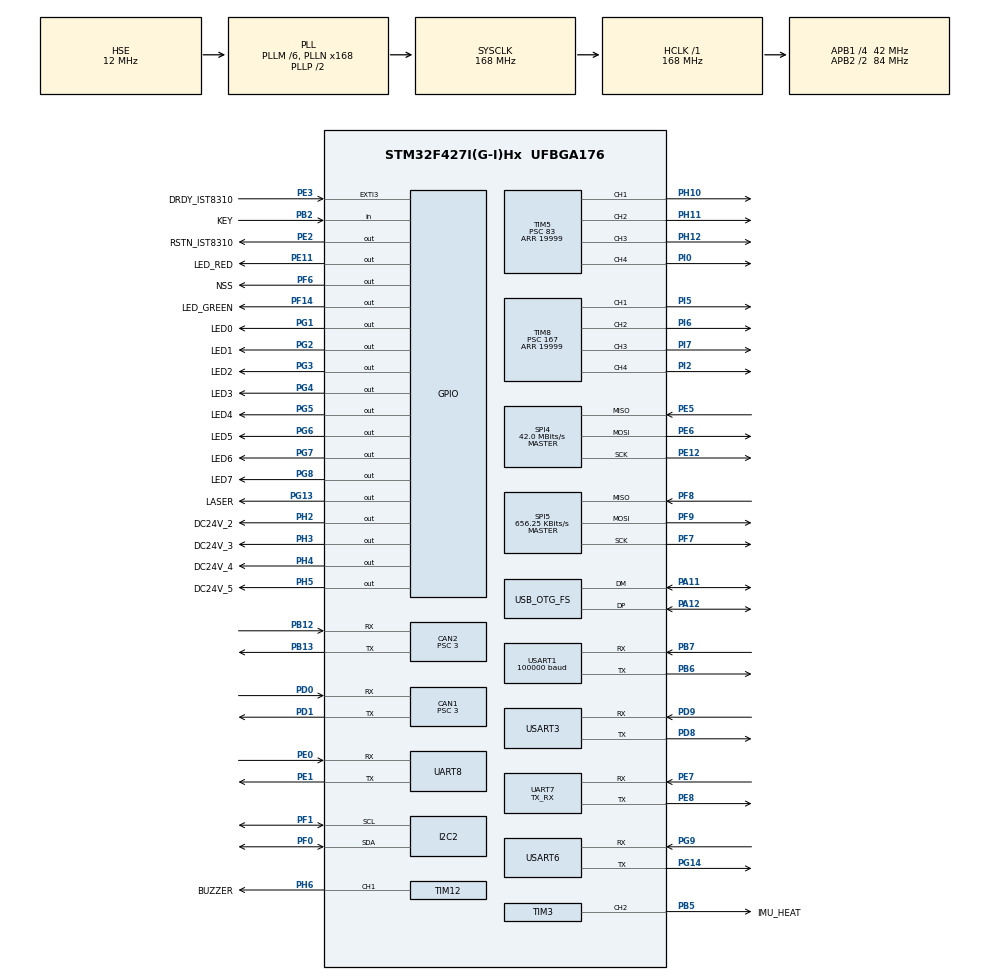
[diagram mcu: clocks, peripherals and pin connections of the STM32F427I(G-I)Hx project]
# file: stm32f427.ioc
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ADC1.Channel-0\#ChannelRegularConversion=ADC_CHANNEL_VREFINT
ADC1.Channel-1\#ChannelRegularConversion=ADC_CHANNEL_VREFINT
ADC1.Channel-2\#ChannelRegularConversion=ADC_CHANNEL_VREFINT
ADC1.Channel-3\#ChannelRegularConversion=ADC_CHANNEL_VREFINT
ADC1.ClockPrescaler=ADC_CLOCK_SYNC_PCLK_DIV4
ADC1.ContinuousConvMode=ENABLE
ADC1.DMAContinuousRequests=DISABLE
ADC1.DataAlign=ADC_DATAALIGN_RIGHT
ADC1.DiscontinuousConvMode=DISABLE
ADC1.EOCSelection=ADC_EOC_SINGLE_CONV
ADC1.EnableAnalogWatchDog=false
ADC1.ExternalTrigConv=ADC_SOFTWARE_START
ADC1.ExternalTrigConvEdge=ADC_EXTERNALTRIGCONVEDGE_NONE
ADC1.InjNumberOfConversion=0
ADC1.NbrOfConversion=4
ADC1.NbrOfConversionFlag=1
ADC1.Rank-0\#ChannelRegularConversion=1
ADC1.Rank-1\#ChannelRegularConversion=2
ADC1.Rank-2\#ChannelRegularConversion=3
ADC1.Rank-3\#ChannelRegularConversion=4
ADC1.Resolution=ADC_RESOLUTION_12B
ADC1.SamplingTime-0\#ChannelRegularConversion=ADC_SAMPLETIME_56CYCLES
ADC1.SamplingTime-1\#ChannelRegularConversion=ADC_SAMPLETIME_56CYCLES
ADC1.SamplingTime-2\#ChannelRegularConversion=ADC_SAMPLETIME_56CYCLES
ADC1.SamplingTime-3\#ChannelRegularConversion=ADC_SAMPLETIME_56CYCLES
ADC1.ScanConvMode=ENABLE
ADC1.master=1
CAN1.ABOM=ENABLE
CAN1.BS1=CAN_BS1_10TQ
CAN1.BS2=CAN_BS2_3TQ
CAN1.CalculateTimeBit=1000
CAN1.CalculateTimeQuantum=71.42857142857143
CAN1.NART=ENABLE
CAN1.Prescaler=3
CAN2.ABOM=ENABLE
CAN2.BS1=CAN_BS1_10TQ
CAN2.BS2=CAN_BS2_3TQ
CAN2.CalculateTimeBit=1000
CAN2.CalculateTimeQuantum=71.42857142857143
CAN2.NART=ENABLE
CAN2.Prescaler=3
Dma.Request0=USART1_RX
Dma.USART1_RX.0.Direction=DMA_PERIPH_TO_MEMORY
Dma.USART1_RX.0.FIFOMode=DMA_FIFOMODE_DISABLE
Dma.USART1_RX.0.Instance=DMA2_Stream2
Dma.USART1_RX.0.MemDataAlignment=DMA_MDATAALIGN_BYTE
Dma.USART1_RX.0.MemInc=DMA_MINC_ENABLE
Dma.USART1_RX.0.Mode=DMA_NORMAL
Dma.USART1_RX.0.PeriphDataAlignment=DMA_PDATAALIGN_BYTE
Dma.USART1_RX.0.PeriphInc=DMA_PINC_DISABLE
Dma.USART1_RX.0.Priority=DMA_PRIORITY_LOW
FREERTOS.INCLUDE_eTaskGetState=1
FREERTOS.INCLUDE_pcTaskGetTaskName=1
FREERTOS.INCLUDE_uxTaskGetStackHighWaterMark=1
FREERTOS.INCLUDE_vTaskCleanUpResources=1
FREERTOS.INCLUDE_vTaskDelayUntil=1
FREERTOS.INCLUDE_xQueueGetMutexHolder=1
FREERTOS.INCLUDE_xSemaphoreGetMutexHolder=1
FREERTOS.INCLUDE_xTaskAbortDelay=1
FREERTOS.INCLUDE_xTaskGetCurrentTaskHandle=1
FREERTOS.INCLUDE_xTaskGetHandle=1
FREERTOS.Tasks01=defaultTask,-3,128,StartDefaultTask,Default,NULL,Dynamic,NULL,NULL
FREERTOS.configTOTAL_HEAP_SIZE=32768
IWDG.Prescaler=IWDG_PRESCALER_32
IWDG.Reload=1500
Mcu.Family=STM32F4
Mcu.Name=STM32F427I(G-I)Hx
Mcu.Package=UFBGA176
NVIC.CAN1_RX0_IRQn=true\:5\:0\:true\:false\:true\:true\:true\:true
NVIC.CAN2_RX0_IRQn=true\:5\:0\:true\:false\:true\:true\:true\:true
NVIC.DMA2_Stream2_IRQn=true\:8\:0\:true\:false\:true\:true\:false\:true
NVIC.OTG_FS_IRQn=true\:9\:0\:true\:false\:true\:true\:false\:true
NVIC.PriorityGroup=NVIC_PRIORITYGROUP_4
NVIC.TIM6_DAC_IRQn=true\:6\:0\:true\:false\:true\:true\:true\:true
NVIC.TIM8_TRG_COM_TIM14_IRQn=true\:0\:0\:false\:false\:true\:false\:false\:true
NVIC.TimeBase=TIM8_TRG_COM_TIM14_IRQn
NVIC.TimeBaseIP=TIM14
NVIC.UART7_IRQn=true\:8\:0\:true\:false\:true\:true\:true\:true
NVIC.UART8_IRQn=true\:8\:0\:true\:false\:true\:true\:true\:true
NVIC.USART1_IRQn=true\:6\:0\:true\:false\:true\:true\:true\:true
NVIC.USART3_IRQn=true\:8\:0\:true\:false\:true\:true\:true\:true
NVIC.USART6_IRQn=true\:8\:0\:true\:false\:true\:true\:true\:true
PA11.Mode=Device_Only
PA11.Signal=USB_OTG_FS_DM
PA12.Mode=Device_Only
PA12.Signal=USB_OTG_FS_DP
PA13.Mode=Serial_Wire
PA13.Signal=SYS_JTMS-SWDIO
PA14.Mode=Serial_Wire
PA14.Signal=SYS_JTCK-SWCLK
PB12.Mode=Slave
PB12.Signal=CAN2_RX
PB13.Mode=Slave
PB13.Signal=CAN2_TX
PB2/BOOT1.GPIO_Label=KEY
PB2/BOOT1.GPIO_PuPd=GPIO_PULLDOWN
PB2/BOOT1.Signal=GPIO_Input
PB5.GPIO_Label=IMU_HEAT
PB5.GPIO_Speed=GPIO_SPEED_FREQ_HIGH
PB5.Signal=S_TIM3_CH2
PB6.Mode=Asynchronous
PB6.Signal=USART1_TX
PB7.Mode=Asynchronous
PB7.Signal=USART1_RX
PC14/OSC32_IN.Mode=LSE-External-Oscillator
PC14/OSC32_IN.Signal=RCC_OSC32_IN
PC15/OSC32_OUT.Mode=LSE-External-Oscillator
PC15/OSC32_OUT.Signal=RCC_OSC32_OUT
PD0.Mode=Master
PD0.Signal=CAN1_RX
PD1.Mode=Master
PD1.Signal=CAN1_TX
PD8.Mode=Asynchronous
PD8.Signal=USART3_TX
PD9.Mode=Asynchronous
PD9.Signal=USART3_RX
PE0.Mode=Asynchronous
PE0.Signal=UART8_RX
PE1.Mode=Asynchronous
PE1.Signal=UART8_TX
PE11.GPIO_Label=LED_RED
PE11.GPIO_PuPd=GPIO_NOPULL
PE11.Signal=GPIO_Output
PE12.Mode=Full_Duplex_Master
PE12.Signal=SPI4_SCK
PE2.GPIO_Label=RSTN_IST8310
PE2.GPIO_PuPd=GPIO_PULLUP
PE2.Signal=GPIO_Output
PE3.GPIO_Label=DRDY_IST8310
PE3.GPIO_PuPd=GPIO_PULLUP
PE3.Signal=GPXTI3
PE5.Mode=Full_Duplex_Master
PE5.Signal=SPI4_MISO
PE6.Mode=Full_Duplex_Master
PE6.Signal=SPI4_MOSI
PE7.Mode=Asynchronous
PE7.Signal=UART7_RX
PE8.Mode=Asynchronous
PE8.Signal=UART7_TX
PF0.Mode=I2C
PF0.Signal=I2C2_SDA
PF1.Mode=I2C
PF1.Signal=I2C2_SCL
PF14.GPIO_Label=LED_GREEN
PF14.GPIO_PuPd=GPIO_NOPULL
PF14.Signal=GPIO_Output
PF6.GPIO_Label=NSS
PF6.Signal=GPIO_Output
PF7.Mode=Full_Duplex_Master
PF7.Signal=SPI5_SCK
PF8.Mode=Full_Duplex_Master
PF8.Signal=SPI5_MISO
PF9.Mode=Full_Duplex_Master
PF9.Signal=SPI5_MOSI
PG1.GPIO_Label=LED0
PG1.GPIO_PuPd=GPIO_NOPULL
PG1.Signal=GPIO_Output
PG13.GPIO_Label=LASER
PG13.Signal=GPIO_Output
PG14.Mode=Asynchronous
PG14.Signal=USART6_TX
PG2.GPIO_Label=LED1
PG2.GPIO_PuPd=GPIO_NOPULL
PG2.Signal=GPIO_Output
PG3.GPIO_Label=LED2
PG3.Signal=GPIO_Output
PG4.GPIO_Label=LED3
PG4.Signal=GPIO_Output
PG5.GPIO_Label=LED4
PG5.Signal=GPIO_Output
PG6.GPIO_Label=LED5
PG6.Signal=GPIO_Output
PG7.GPIO_Label=LED6
PG7.Signal=GPIO_Output
PG8.GPIO_Label=LED7
PG8.Signal=GPIO_Output
PG9.Mode=Asynchronous
PG9.Signal=USART6_RX
PH0/OSC_IN.Mode=HSE-External-Oscillator
PH0/OSC_IN.Signal=RCC_OSC_IN
PH1/OSC_OUT.Mode=HSE-External-Oscillator
PH1/OSC_OUT.Signal=RCC_OSC_OUT
PH10.Signal=S_TIM5_CH1
PH11.Signal=S_TIM5_CH2
PH12.Signal=S_TIM5_CH3
PH2.GPIO_Label=DC24V_2
PH2.Signal=GPIO_Output
PH3.GPIO_Label=DC24V_3
PH3.Signal=GPIO_Output
PH4.GPIO_Label=DC24V_4
PH4.Signal=GPIO_Output
PH5.GPIO_Label=DC24V_5
PH5.Signal=GPIO_Output
PH6.GPIO_Label=BUZZER
PH6.GPIO_Speed=GPIO_SPEED_FREQ_HIGH
PH6.Signal=S_TIM12_CH1
PI0.Signal=S_TIM5_CH4
PI2.GPIO_Speed=GPIO_SPEED_FREQ_HIGH
PI2.Signal=S_TIM8_CH4
PI5.GPIO_Speed=GPIO_SPEED_FREQ_HIGH
PI5.Signal=S_TIM8_CH1
PI6.GPIO_Speed=GPIO_SPEED_FREQ_HIGH
PI6.Signal=S_TIM8_CH2
PI7.GPIO_Speed=GPIO_SPEED_FREQ_HIGH
PI7.Signal=S_TIM8_CH3
ProjectManager.HeapSize=0x8000
ProjectManager.StackSize=0x8000
ProjectManager.TargetToolchain=MDK-ARM V5
RCC.48MHZClocksFreq_Value=48000000
RCC.AHBFreq_Value=168000000
RCC.APB1CLKDivider=RCC_HCLK_DIV4
RCC.APB1Freq_Value=42000000
RCC.APB1TimFreq_Value=84000000
RCC.APB2CLKDivider=RCC_HCLK_DIV2
RCC.APB2Freq_Value=84000000
RCC.APB2TimFreq_Value=168000000
RCC.CortexFreq_Value=168000000
RCC.HCLKFreq_Value=168000000
RCC.HSE_VALUE=12000000
RCC.HSI_VALUE=16000000
RCC.PLLM=6
RCC.PLLN=168
RCC.PLLQ=7
RCC.SYSCLKFreq_VALUE=168000000
RCC.SYSCLKSource=RCC_SYSCLKSOURCE_PLLCLK
RCC.VCOOutputFreq_Value=336000000
SH.S_TIM12_CH1.0=TIM12_CH1,PWM Generation1 CH1
SH.S_TIM3_CH2.0=TIM3_CH2,PWM Generation2 CH2
SH.S_TIM5_CH1.0=TIM5_CH1,PWM Generation1 CH1
SH.S_TIM5_CH2.0=TIM5_CH2,PWM Generation2 CH2
SH.S_TIM5_CH3.0=TIM5_CH3,PWM Generation3 CH3
SH.S_TIM5_CH4.0=TIM5_CH4,PWM Generation4 CH4
SH.S_TIM8_CH1.0=TIM8_CH1,PWM Generation1 CH1
SH.S_TIM8_CH2.0=TIM8_CH2,PWM Generation2 CH2
SH.S_TIM8_CH3.0=TIM8_CH3,PWM Generation3 CH3
SH.S_TIM8_CH4.0=TIM8_CH4,PWM Generation4 CH4
SPI4.CalculateBaudRate=42.0 MBits/s
SPI4.Direction=SPI_DIRECTION_2LINES
SPI4.Mode=SPI_MODE_MASTER
SPI4.VirtualType=VM_MASTER
SPI5.BaudRatePrescaler=SPI_BAUDRATEPRESCALER_128
SPI5.CalculateBaudRate=656.25 KBits/s
SPI5.Direction=SPI_DIRECTION_2LINES
SPI5.Mode=SPI_MODE_MASTER
SPI5.VirtualType=VM_MASTER
TIM12.Channel-PWM\ Generation1\ CH1=TIM_CHANNEL_1
TIM12.Period=65535
TIM12.Prescaler=167
TIM12.Pulse-PWM\ Generation1\ CH1=1000
TIM3.Channel-PWM\ Generation2\ CH2=TIM_CHANNEL_2
TIM3.Period=4999
TIM5.Channel-PWM\ Generation1\ CH1=TIM_CHANNEL_1
TIM5.Channel-PWM\ Generation2\ CH2=TIM_CHANNEL_2
TIM5.Channel-PWM\ Generation3\ CH3=TIM_CHANNEL_3
TIM5.Channel-PWM\ Generation4\ CH4=TIM_CHANNEL_4
TIM5.Period=19999
TIM5.Prescaler=83
TIM6.Period=999
TIM6.Prescaler=83
TIM8.Channel-PWM\ Generation1\ CH1=TIM_CHANNEL_1
TIM8.Channel-PWM\ Generation2\ CH2=TIM_CHANNEL_2
TIM8.Channel-PWM\ Generation3\ CH3=TIM_CHANNEL_3
TIM8.Channel-PWM\ Generation4\ CH4=TIM_CHANNEL_4
TIM8.Period=19999
TIM8.Prescaler=167
UART7.Mode=MODE_TX_RX
UART7.OverSampling=UART_OVERSAMPLING_16
UART7.VirtualMode=Asynchronous
UART7.WordLength=WORDLENGTH_8B
UART8.VirtualMode=Asynchronous
USART1.BaudRate=100000
USART1.Mode=MODE_RX
USART1.Parity=PARITY_EVEN
USART1.VirtualMode=VM_ASYNC
USART1.WordLength=WORDLENGTH_9B
USART3.VirtualMode=VM_ASYNC
USART6.VirtualMode=VM_ASYNC
USB_DEVICE.CLASS_NAME_FS=CDC
USB_DEVICE.VirtualMode-CDC_FS=Cdc
USB_DEVICE.VirtualModeFS=Cdc_FS
USB_OTG_FS.VirtualMode=Device_Only
VP_ADC1_Vref_Input.Mode=IN-Vrefint
VP_FREERTOS_VS_CMSIS_V1.Mode=CMSIS_V1
VP_IWDG_VS_IWDG.Mode=IWDG_Activate
VP_SYS_VS_tim14.Mode=TIM14
VP_TIM12_VS_ClockSourceINT.Mode=Internal
VP_TIM6_VS_ClockSourceINT.Mode=Enable_Timer
VP_USB_DEVICE_VS_USB_DEVICE_CDC_FS.Mode=CDC_FS
board=RM_frame

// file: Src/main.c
/* USER CODE BEGIN Header */
/**
  ******************************************************************************
  * @file           : main.c
  * @brief          : Main program body
  ******************************************************************************
  * @attention
  *
  * <h2><center>&copy; Copyright (c) 2023 STMicroelectronics.
  * All rights reserved.</center></h2>
  *
  * This software component is licensed by ST under BSD 3-Clause license,
  * the "License"; You may not use this file except in compliance with the
  * License. You may obtain a copy of the License at:
  *                        opensource.org/licenses/BSD-3-Clause
  *
  ******************************************************************************
  */
/* USER CODE END Header */

#include "main.h"
#include "cmsis_os.h"
#include "adc.h"
#include "can.h"
#include "dma.h"
#include "i2c.h"
#include "iwdg.h"
#include "spi.h"
#include "tim.h"
#include "usart.h"
#include "usb_device.h"
#include "gpio.h"

void SystemClock_Config(void);
void MX_FREERTOS_Init(void);

int main(void)
{

  /* MCU Configuration--------------------------------------------------------*/

  /* Reset of all peripherals, Initializes the Flash interface and the Systick. */
  HAL_Init();

  /* Configure the system clock */
  SystemClock_Config();

  /* Initialize all configured peripherals */
  MX_GPIO_Init();
  MX_DMA_Init();
  MX_CAN1_Init();
  MX_CAN2_Init();
  MX_SPI5_Init();
  MX_USART1_UART_Init();
  MX_TIM6_Init();
  MX_TIM12_Init();
  MX_USART6_UART_Init();
  MX_USART3_UART_Init();
  MX_UART7_Init();
  MX_ADC1_Init();
  MX_UART8_Init();
  MX_TIM8_Init();
  MX_TIM3_Init();
  MX_I2C2_Init();
  MX_SPI4_Init();
  MX_TIM5_Init();
  MX_IWDG_Init();
  /* USER CODE BEGIN 2 */
  HAL_GPIO_WritePin(GPIOH, DC24V_2_Pin|DC24V_3_Pin|DC24V_4_Pin|DC24V_5_Pin, GPIO_PIN_SET);
  /* USER CODE END 2 */

  /* Call init function for freertos objects (in freertos.c) */
  MX_FREERTOS_Init();

  /* Start scheduler */
  osKernelStart();

  /* We should never get here as control is now taken by the scheduler */

  /* Infinite loop */
  while (1)
  {

  }
}

void SystemClock_Config(void)
{
  RCC_OscInitTypeDef RCC_OscInitStruct = {0};
  RCC_ClkInitTypeDef RCC_ClkInitStruct = {0};

  /** Configure the main internal regulator output voltage
  */
  __HAL_RCC_PWR_CLK_ENABLE();
  __HAL_PWR_VOLTAGESCALING_CONFIG(PWR_REGULATOR_VOLTAGE_SCALE1);
  /** Initializes the CPU, AHB and APB busses clocks
  */
  RCC_OscInitStruct.OscillatorType = RCC_OSCILLATORTYPE_LSI|RCC_OSCILLATORTYPE_HSE;
  RCC_OscInitStruct.HSEState = RCC_HSE_ON;
  RCC_OscInitStruct.LSIState = RCC_LSI_ON;
  RCC_OscInitStruct.PLL.PLLState = RCC_PLL_ON;
  RCC_OscInitStruct.PLL.PLLSource = RCC_PLLSOURCE_HSE;
  RCC_OscInitStruct.PLL.PLLM = 6;
  RCC_OscInitStruct.PLL.PLLN = 168;
  RCC_OscInitStruct.PLL.PLLP = RCC_PLLP_DIV2;
  RCC_OscInitStruct.PLL.PLLQ = 7;
  if (HAL_RCC_OscConfig(&RCC_OscInitStruct) != HAL_OK)
  {
    Error_Handler();
  }
  /** Initializes the CPU, AHB and APB busses clocks
  */
  RCC_ClkInitStruct.ClockType = RCC_CLOCKTYPE_HCLK|RCC_CLOCKTYPE_SYSCLK
                              |RCC_CLOCKTYPE_PCLK1|RCC_CLOCKTYPE_PCLK2;
  RCC_ClkInitStruct.SYSCLKSource = RCC_SYSCLKSOURCE_PLLCLK;
  RCC_ClkInitStruct.AHBCLKDivider = RCC_SYSCLK_DIV1;
  RCC_ClkInitStruct.APB1CLKDivider = RCC_HCLK_DIV4;
  RCC_ClkInitStruct.APB2CLKDivider = RCC_HCLK_DIV2;

  if (HAL_RCC_ClockConfig(&RCC_ClkInitStruct, FLASH_LATENCY_5) != HAL_OK)
  {
    Error_Handler();
  }
}

void HAL_TIM_PeriodElapsedCallback(TIM_HandleTypeDef *htim)
{
  if (htim->Instance == TIM14) {
    HAL_IncTick();
  }
}

void Error_Handler(void)
{
}

/************************ (C) COPYRIGHT STMicroelectronics *****END OF FILE****/
